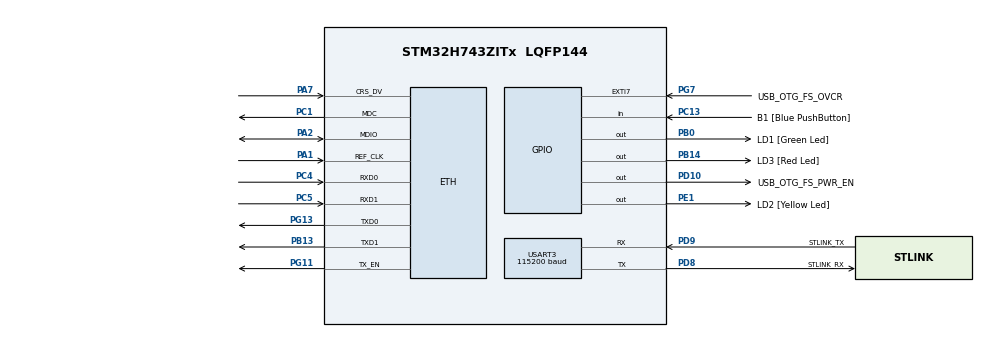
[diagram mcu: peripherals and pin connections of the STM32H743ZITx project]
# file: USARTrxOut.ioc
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Dma.Request0=USART3_TX
Dma.USART3_TX.0.Direction=DMA_MEMORY_TO_PERIPH
Dma.USART3_TX.0.EventEnable=DISABLE
Dma.USART3_TX.0.FIFOMode=DMA_FIFOMODE_DISABLE
Dma.USART3_TX.0.Instance=DMA1_Stream0
Dma.USART3_TX.0.MemDataAlignment=DMA_MDATAALIGN_BYTE
Dma.USART3_TX.0.MemInc=DMA_MINC_ENABLE
Dma.USART3_TX.0.Mode=DMA_NORMAL
Dma.USART3_TX.0.PeriphDataAlignment=DMA_PDATAALIGN_BYTE
Dma.USART3_TX.0.PeriphInc=DMA_PINC_DISABLE
Dma.USART3_TX.0.Polarity=HAL_DMAMUX_REQ_GEN_RISING
Dma.USART3_TX.0.Priority=DMA_PRIORITY_HIGH
Dma.USART3_TX.0.RequestNumber=1
Dma.USART3_TX.0.SignalID=NONE
Dma.USART3_TX.0.SyncEnable=DISABLE
Dma.USART3_TX.0.SyncPolarity=HAL_DMAMUX_SYNC_NO_EVENT
Dma.USART3_TX.0.SyncRequestNumber=1
Dma.USART3_TX.0.SyncSignalID=NONE
ETH.MediaInterface=HAL_ETH_RMII_MODE
Mcu.Family=STM32H7
Mcu.Name=STM32H743ZITx
Mcu.Package=LQFP144
NVIC.DMA1_Stream0_IRQn=true\:0\:0\:false\:false\:true\:false\:true\:true
NVIC.PriorityGroup=NVIC_PRIORITYGROUP_4
NVIC.USART3_IRQn=true\:0\:0\:false\:false\:true\:true\:true\:true
PA1.Mode=RMII
PA1.Signal=ETH_REF_CLK
PA11.Signal=USB_OTG_FS_DM
PA12.Signal=USB_OTG_FS_DP
PA2.Mode=RMII
PA2.Signal=ETH_MDIO
PA7.Mode=RMII
PA7.Signal=ETH_CRS_DV
PA8.Signal=USB_OTG_FS_SOF
PA9.Signal=USB_OTG_FS_VBUS
PB0.GPIO_Label=LD1 [Green Led]
PB0.Signal=GPIO_Output
PB13.Mode=RMII
PB13.Signal=ETH_TXD1
PB14.GPIO_Label=LD3 [Red Led]
PB14.Signal=GPIO_Output
PC1.Mode=RMII
PC1.Signal=ETH_MDC
PC13.GPIO_Label=B1 [Blue PushButton]
PC13.Signal=GPIO_Input
PC14-OSC32_IN\ (OSC32_IN).Mode=LSE-External-Oscillator
PC14-OSC32_IN\ (OSC32_IN).Signal=RCC_OSC32_IN
PC15-OSC32_OUT\ (OSC32_OUT).Mode=LSE-External-Oscillator
PC15-OSC32_OUT\ (OSC32_OUT).Signal=RCC_OSC32_OUT
PC4.Mode=RMII
PC4.Signal=ETH_RXD0
PC5.Mode=RMII
PC5.Signal=ETH_RXD1
PD10.GPIO_Label=USB_OTG_FS_PWR_EN
PD10.Signal=GPIO_Output
PD8.GPIO_Label=STLINK_RX
PD8.Mode=Asynchronous
PD8.Signal=USART3_TX
PD9.GPIO_Label=STLINK_TX
PD9.Mode=Asynchronous
PD9.Signal=USART3_RX
PE1.GPIO_Label=LD2 [Yellow Led]
PE1.Signal=GPIO_Output
PG11.Mode=RMII
PG11.Signal=ETH_TX_EN
PG13.Mode=RMII
PG13.Signal=ETH_TXD0
PG7.GPIO_Label=USB_OTG_FS_OVCR
PG7.Signal=GPXTI7
PH0-OSC_IN\ (PH0).Mode=HSE-External-Oscillator
PH0-OSC_IN\ (PH0).Signal=RCC_OSC_IN
PH1-OSC_OUT\ (PH1).Mode=HSE-External-Oscillator
PH1-OSC_OUT\ (PH1).Signal=RCC_OSC_OUT
ProjectManager.HeapSize=0x200
ProjectManager.StackSize=0x400
ProjectManager.TargetToolchain=TrueSTUDIO
RCC.ADCFreq_Value=16125000
RCC.APB1Freq_Value=64000000
RCC.APB2Freq_Value=64000000
RCC.APB3Freq_Value=64000000
RCC.APB4Freq_Value=64000000
RCC.CortexFreq_Value=64000000
RCC.DIVM1=1
RCC.DIVN1=24
RCC.DIVQ1=4
RCC.HCLKFreq_Value=64000000
RCC.HSE_VALUE=8000000
RCC.PLLFRACN=0
RCC.PLLSourceVirtual=RCC_PLLSOURCE_HSE
RCC.PWR_Regulator_Voltage_Scale=PWR_REGULATOR_VOLTAGE_SCALE2
RCC.SYSCLKFreq_VALUE=64000000
RCC.USBFreq_Value=48000000
USART3.BaudRate=115200
USART3.VirtualMode-Asynchronous=VM_ASYNC
board=NUCLEO-H743ZI2

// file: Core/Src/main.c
/* USER CODE BEGIN Header */
/**
  ******************************************************************************
  * @file           : main.c
  * @brief          : Main program body
  ******************************************************************************
  * @attention
  *
  * Copyright (c) 2024 STMicroelectronics.
  * All rights reserved.
  *
  * This software is licensed under terms that can be found in the LICENSE file
  * in the root directory of this software component.
  * If no LICENSE file comes with this software, it is provided AS-IS.
  *
  ******************************************************************************
  */
/* USER CODE END Header */
#include "main.h"
#include "string.h"

#if defined ( __ICCARM__ ) /*!< IAR Compiler */
#pragma location=0x30000000
ETH_DMADescTypeDef  DMARxDscrTab[ETH_RX_DESC_CNT]; /* Ethernet Rx DMA Descriptors */
#pragma location=0x30000200
ETH_DMADescTypeDef  DMATxDscrTab[ETH_TX_DESC_CNT]; /* Ethernet Tx DMA Descriptors */
#pragma location=0x30000260
uint8_t Rx_Buff[ETH_RX_DESC_CNT][ETH_MAX_PACKET_SIZE]; /* Ethernet Receive Buffers */

#elif defined ( __CC_ARM )  /* MDK ARM Compiler */

__attribute__((at(0x30000000))) ETH_DMADescTypeDef  DMARxDscrTab[ETH_RX_DESC_CNT]; /* Ethernet Rx DMA Descriptors */
__attribute__((at(0x30000200))) ETH_DMADescTypeDef  DMATxDscrTab[ETH_TX_DESC_CNT]; /* Ethernet Tx DMA Descriptors */
__attribute__((at(0x30000260))) uint8_t Rx_Buff[ETH_RX_DESC_CNT][ETH_MAX_PACKET_SIZE]; /* Ethernet Receive Buffer */

#elif defined ( __GNUC__ ) /* GNU Compiler */
ETH_DMADescTypeDef DMARxDscrTab[ETH_RX_DESC_CNT] __attribute__((section(".RxDecripSection"))); /* Ethernet Rx DMA Descriptors */
ETH_DMADescTypeDef DMATxDscrTab[ETH_TX_DESC_CNT] __attribute__((section(".TxDecripSection")));   /* Ethernet Tx DMA Descriptors */
uint8_t Rx_Buff[ETH_RX_DESC_CNT][ETH_MAX_PACKET_SIZE] __attribute__((section(".RxArraySection"))); /* Ethernet Receive Buffers */
#endif

ETH_TxPacketConfig TxConfig;

ETH_HandleTypeDef heth;

UART_HandleTypeDef huart3;
DMA_HandleTypeDef hdma_usart3_tx;

void SystemClock_Config(void);
static void MX_GPIO_Init(void);
static void MX_ETH_Init(void);
static void MX_DMA_Init(void);
static void MX_USART3_UART_Init(void);

int main(void)
{

  /* MCU Configuration--------------------------------------------------------*/

  /* Reset of all peripherals, Initializes the Flash interface and the Systick. */
  HAL_Init();

  /* Configure the system clock */
  SystemClock_Config();

  /* Initialize all configured peripherals */
  MX_GPIO_Init();
  MX_ETH_Init();
  MX_DMA_Init();
  MX_USART3_UART_Init();
  /* USER CODE BEGIN 2 */
  uint8_t str[8];
  for(int i =0;i<8;i++)
    {
  	  str[i]=i;
    }
  /* USER CODE END 2 */

  /* Infinite loop */
  while (1)
  {
	  HAL_UART_Transmit_DMA(&huart3, str, sizeof(str)-1);
	  HAL_Delay(100);
  }
}

void SystemClock_Config(void)
{
  RCC_OscInitTypeDef RCC_OscInitStruct = {0};
  RCC_ClkInitTypeDef RCC_ClkInitStruct = {0};

  /** Supply configuration update enable
  */
  HAL_PWREx_ConfigSupply(PWR_LDO_SUPPLY);

  /** Configure the main internal regulator output voltage
  */
  __HAL_PWR_VOLTAGESCALING_CONFIG(PWR_REGULATOR_VOLTAGE_SCALE2);

  while(!__HAL_PWR_GET_FLAG(PWR_FLAG_VOSRDY)) {}

  /** Initializes the RCC Oscillators according to the specified parameters
  * in the RCC_OscInitTypeDef structure.
  */
  RCC_OscInitStruct.OscillatorType = RCC_OSCILLATORTYPE_HSI;
  RCC_OscInitStruct.HSIState = RCC_HSI_DIV1;
  RCC_OscInitStruct.HSICalibrationValue = RCC_HSICALIBRATION_DEFAULT;
  RCC_OscInitStruct.PLL.PLLState = RCC_PLL_NONE;
  if (HAL_RCC_OscConfig(&RCC_OscInitStruct) != HAL_OK)
  {
    Error_Handler();
  }

  /** Initializes the CPU, AHB and APB buses clocks
  */
  RCC_ClkInitStruct.ClockType = RCC_CLOCKTYPE_HCLK|RCC_CLOCKTYPE_SYSCLK
                              |RCC_CLOCKTYPE_PCLK1|RCC_CLOCKTYPE_PCLK2
                              |RCC_CLOCKTYPE_D3PCLK1|RCC_CLOCKTYPE_D1PCLK1;
  RCC_ClkInitStruct.SYSCLKSource = RCC_SYSCLKSOURCE_HSI;
  RCC_ClkInitStruct.SYSCLKDivider = RCC_SYSCLK_DIV1;
  RCC_ClkInitStruct.AHBCLKDivider = RCC_HCLK_DIV1;
  RCC_ClkInitStruct.APB3CLKDivider = RCC_APB3_DIV1;
  RCC_ClkInitStruct.APB1CLKDivider = RCC_APB1_DIV1;
  RCC_ClkInitStruct.APB2CLKDivider = RCC_APB2_DIV1;
  RCC_ClkInitStruct.APB4CLKDivider = RCC_APB4_DIV1;

  if (HAL_RCC_ClockConfig(&RCC_ClkInitStruct, FLASH_LATENCY_1) != HAL_OK)
  {
    Error_Handler();
  }
}

static void MX_ETH_Init(void)
{

   static uint8_t MACAddr[6];

  heth.Instance = ETH;
  MACAddr[0] = 0x00;
  MACAddr[1] = 0x80;
  MACAddr[2] = 0xE1;
  MACAddr[3] = 0x00;
  MACAddr[4] = 0x00;
  MACAddr[5] = 0x00;
  heth.Init.MACAddr = &MACAddr[0];
  heth.Init.MediaInterface = HAL_ETH_RMII_MODE;
  heth.Init.TxDesc = DMATxDscrTab;
  heth.Init.RxDesc = DMARxDscrTab;
  heth.Init.RxBuffLen = 1524;

  if (HAL_ETH_Init(&heth) != HAL_OK)
  {
    Error_Handler();
  }

  memset(&TxConfig, 0 , sizeof(ETH_TxPacketConfig));
  TxConfig.Attributes = ETH_TX_PACKETS_FEATURES_CSUM | ETH_TX_PACKETS_FEATURES_CRCPAD;
  TxConfig.ChecksumCtrl = ETH_CHECKSUM_IPHDR_PAYLOAD_INSERT_PHDR_CALC;
  TxConfig.CRCPadCtrl = ETH_CRC_PAD_INSERT;

}

static void MX_USART3_UART_Init(void)
{

  huart3.Instance = USART3;
  huart3.Init.BaudRate = 115200;
  huart3.Init.WordLength = UART_WORDLENGTH_8B;
  huart3.Init.StopBits = UART_STOPBITS_1;
  huart3.Init.Parity = UART_PARITY_NONE;
  huart3.Init.Mode = UART_MODE_TX_RX;
  huart3.Init.HwFlowCtl = UART_HWCONTROL_NONE;
  huart3.Init.OverSampling = UART_OVERSAMPLING_16;
  huart3.Init.OneBitSampling = UART_ONE_BIT_SAMPLE_DISABLE;
  huart3.Init.ClockPrescaler = UART_PRESCALER_DIV1;
  huart3.AdvancedInit.AdvFeatureInit = UART_ADVFEATURE_NO_INIT;
  if (HAL_UART_Init(&huart3) != HAL_OK)
  {
    Error_Handler();
  }
  if (HAL_UARTEx_SetTxFifoThreshold(&huart3, UART_TXFIFO_THRESHOLD_1_8) != HAL_OK)
  {
    Error_Handler();
  }
  if (HAL_UARTEx_SetRxFifoThreshold(&huart3, UART_RXFIFO_THRESHOLD_1_8) != HAL_OK)
  {
    Error_Handler();
  }
  if (HAL_UARTEx_DisableFifoMode(&huart3) != HAL_OK)
  {
    Error_Handler();
  }

}

static void MX_DMA_Init(void)
{

  /* DMA controller clock enable */
  __HAL_RCC_DMA1_CLK_ENABLE();

  /* DMA interrupt init */
  /* DMA1_Stream0_IRQn interrupt configuration */
  HAL_NVIC_SetPriority(DMA1_Stream0_IRQn, 0, 0);
  HAL_NVIC_EnableIRQ(DMA1_Stream0_IRQn);

}

static void MX_GPIO_Init(void)
{
  GPIO_InitTypeDef GPIO_InitStruct = {0};

  /* GPIO Ports Clock Enable */
  __HAL_RCC_GPIOC_CLK_ENABLE();
  __HAL_RCC_GPIOH_CLK_ENABLE();
  __HAL_RCC_GPIOA_CLK_ENABLE();
  __HAL_RCC_GPIOB_CLK_ENABLE();
  __HAL_RCC_GPIOD_CLK_ENABLE();
  __HAL_RCC_GPIOG_CLK_ENABLE();
  __HAL_RCC_GPIOE_CLK_ENABLE();

  /*Configure GPIO pin Output Level */
  HAL_GPIO_WritePin(GPIOB, LD1_Pin|LD3_Pin, GPIO_PIN_RESET);

  /*Configure GPIO pin Output Level */
  HAL_GPIO_WritePin(USB_OTG_FS_PWR_EN_GPIO_Port, USB_OTG_FS_PWR_EN_Pin, GPIO_PIN_RESET);

  /*Configure GPIO pin Output Level */
  HAL_GPIO_WritePin(LD2_GPIO_Port, LD2_Pin, GPIO_PIN_RESET);

  /*Configure GPIO pin : B1_Pin */
  GPIO_InitStruct.Pin = B1_Pin;
  GPIO_InitStruct.Mode = GPIO_MODE_INPUT;
  GPIO_InitStruct.Pull = GPIO_NOPULL;
  HAL_GPIO_Init(B1_GPIO_Port, &GPIO_InitStruct);

  /*Configure GPIO pins : LD1_Pin LD3_Pin */
  GPIO_InitStruct.Pin = LD1_Pin|LD3_Pin;
  GPIO_InitStruct.Mode = GPIO_MODE_OUTPUT_PP;
  GPIO_InitStruct.Pull = GPIO_NOPULL;
  GPIO_InitStruct.Speed = GPIO_SPEED_FREQ_LOW;
  HAL_GPIO_Init(GPIOB, &GPIO_InitStruct);

  /*Configure GPIO pin : USB_OTG_FS_PWR_EN_Pin */
  GPIO_InitStruct.Pin = USB_OTG_FS_PWR_EN_Pin;
  GPIO_InitStruct.Mode = GPIO_MODE_OUTPUT_PP;
  GPIO_InitStruct.Pull = GPIO_NOPULL;
  GPIO_InitStruct.Speed = GPIO_SPEED_FREQ_LOW;
  HAL_GPIO_Init(USB_OTG_FS_PWR_EN_GPIO_Port, &GPIO_InitStruct);

  /*Configure GPIO pin : USB_OTG_FS_OVCR_Pin */
  GPIO_InitStruct.Pin = USB_OTG_FS_OVCR_Pin;
  GPIO_InitStruct.Mode = GPIO_MODE_IT_RISING;
  GPIO_InitStruct.Pull = GPIO_NOPULL;
  HAL_GPIO_Init(USB_OTG_FS_OVCR_GPIO_Port, &GPIO_InitStruct);

  /*Configure GPIO pins : PA8 PA11 PA12 */
  GPIO_InitStruct.Pin = GPIO_PIN_8|GPIO_PIN_11|GPIO_PIN_12;
  GPIO_InitStruct.Mode = GPIO_MODE_AF_PP;
  GPIO_InitStruct.Pull = GPIO_NOPULL;
  GPIO_InitStruct.Speed = GPIO_SPEED_FREQ_LOW;
  GPIO_InitStruct.Alternate = GPIO_AF10_OTG1_FS;
  HAL_GPIO_Init(GPIOA, &GPIO_InitStruct);

  /*Configure GPIO pin : LD2_Pin */
  GPIO_InitStruct.Pin = LD2_Pin;
  GPIO_InitStruct.Mode = GPIO_MODE_OUTPUT_PP;
  GPIO_InitStruct.Pull = GPIO_NOPULL;
  GPIO_InitStruct.Speed = GPIO_SPEED_FREQ_LOW;
  HAL_GPIO_Init(LD2_GPIO_Port, &GPIO_InitStruct);

}

void Error_Handler(void)
{
  __disable_irq();
  while (1)
  {
  }
}
